# ES32F0xx register map
File version: 1.0
Registers are 32-bit, read-write, reset 0x0 unless marked. A register's access mark holds for its fields unless they carry their own. Offsets are from the block's base; [hi:lo] are bit positions; {n}, {i} and the like mark numbered series; 'fields as' and 'values as' point back to an identical list.

## USART0 — Universal Synchronous
Base 0x40005000
Same registers: USART1 0x40005400
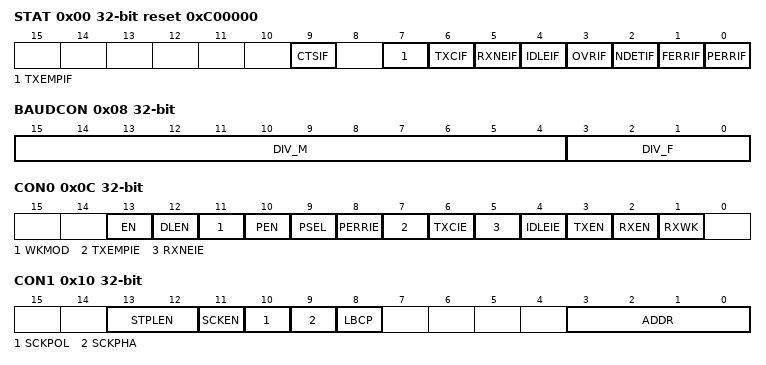
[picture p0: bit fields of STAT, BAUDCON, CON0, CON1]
0x00 STAT read reset 0xC00000
  [9] CTSIF, [7] TXEMPIF, [6] TXCIF, [5] RXNEIF, [4] IDLEIF, [3] OVRIF, [2] NDETIF, [1] FERRIF, [0] PERRIF
0x04 DATA
  [8:0] VAL
0x08 BAUDCON
  [15:4] DIV_M, [3:0] DIV_F
0x0C CON0
  [13] EN, [12] DLEN, [11] WKMOD, [10] PEN, [9] PSEL, [8] PERRIE, [7] TXEMPIE, [6] TXCIE, [5] RXNEIE, [4] IDLEIE, [3] TXEN, [2] RXEN, [1] RXWK
0x10 CON1
  [13:12] STPLEN, [11] SCKEN, [10] SCKPOL, [9] SCKPHA, [8] LBCP, [3:0] ADDR
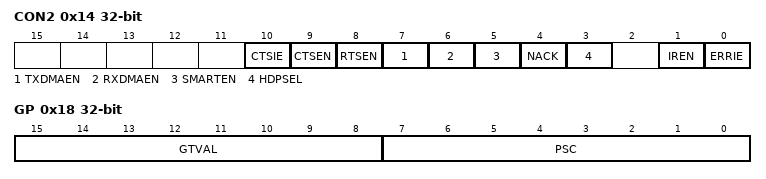
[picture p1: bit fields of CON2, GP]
0x14 CON2
  [10] CTSIE, [9] CTSEN, [8] RTSEN, [7] TXDMAEN, [6] RXDMAEN, [5] SMARTEN, [4] NACK, [3] HDPSEL, [1] IREN, [0] ERRIE
0x18 GP
  [15:8] GTVAL, [7:0] PSC

## UART0 — Universal Asynchronous
Base 0x40004000
Same registers: UART1 0x40004400, UART2 0x40004800, UART3 0x40004C00
0x00 RBR ro
  [8:0] RBR
0x04 TBR
  [8:0] TBR
0x08 BRR
  [15:0] BRR
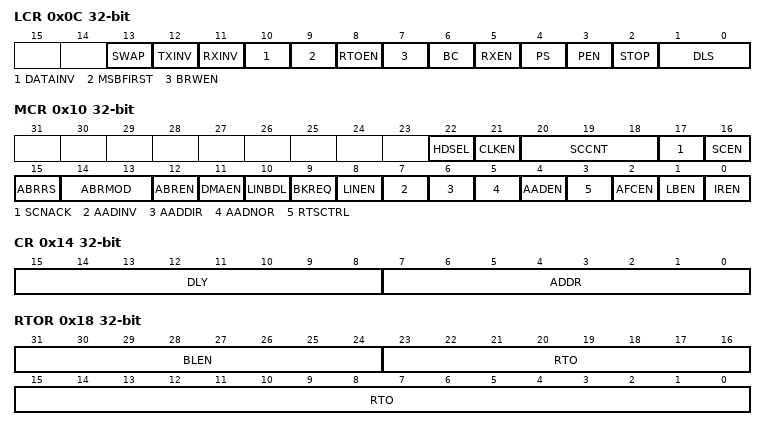
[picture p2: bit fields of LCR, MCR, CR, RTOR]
0x0C LCR
  [13] SWAP, [12] TXINV, [11] RXINV, [10] DATAINV, [9] MSBFIRST, [8] RTOEN, [7] BRWEN, [6] BC, [5] RXEN, [4] PS, [3] PEN, [2] STOP, [1:0] DLS
0x10 MCR
  [22] HDSEL, [21] CLKEN, [20:18] SCCNT, [17] SCNACK, [16] SCEN, [15] ABRRS, [14:13] ABRMOD, [12] ABREN, [11] DMAEN, [10] LINBDL, [9] BKREQ, [8] LINEN, [7] AADINV, [6] AADDIR, [5] AADNOR, [4] AADEN, [3] RTSCTRL, [2] AFCEN, [1] LBEN, [0] IREN
0x14 CR
  [15:8] DLY, [7:0] ADDR
0x18 RTOR
  [31:24] BLEN, [23:0] RTO
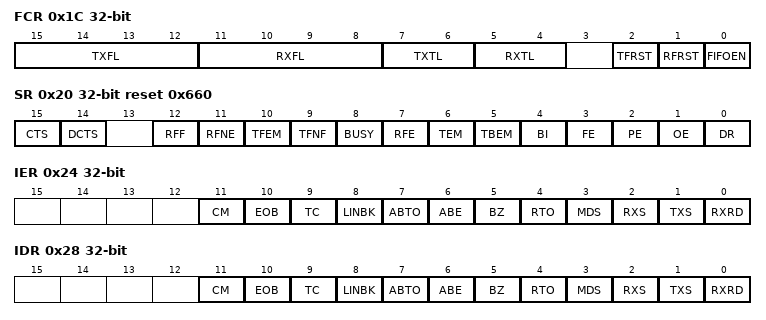
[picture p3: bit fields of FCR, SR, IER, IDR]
0x1C FCR
  [15:12] TXFL, [11:8] RXFL, [7:6] TXTL, [5:4] RXTL, [2] TFRST, [1] RFRST, [0] FIFOEN
0x20 SR ro reset 0x660
  [15] CTS, [14] DCTS, [12] RFF, [11] RFNE, [10] TFEM, [9] TFNF, [8] BUSY, [7] RFE, [6] TEM, [5] TBEM, [4] BI, [3] FE, [2] PE, [1] OE, [0] DR
0x24 IER
  [11] CM, [10] EOB, [9] TC, [8] LINBK, [7] ABTO, [6] ABE, [5] BZ, [4] RTO, [3] MDS, [2] RXS, [1] TXS, [0] RXRD
0x28 IDR
  fields as IER
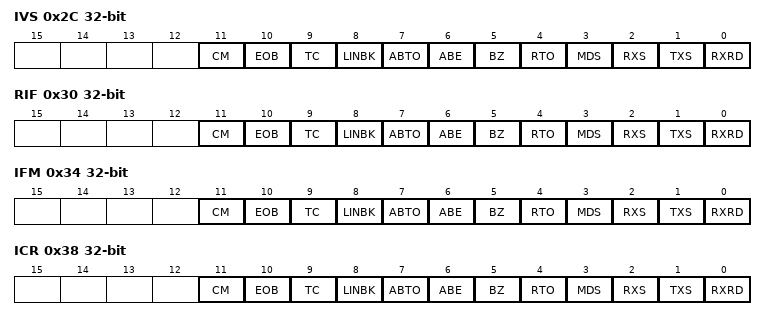
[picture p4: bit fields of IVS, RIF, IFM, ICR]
0x2C IVS ro
  fields as IER
0x30 RIF ro
  fields as IER
0x34 IFM ro
  fields as IER
0x38 ICR
  fields as IER

## ADC0 — Analog-to-digital converter
Base 0x40042000
Same registers: ADC1 0x40042400
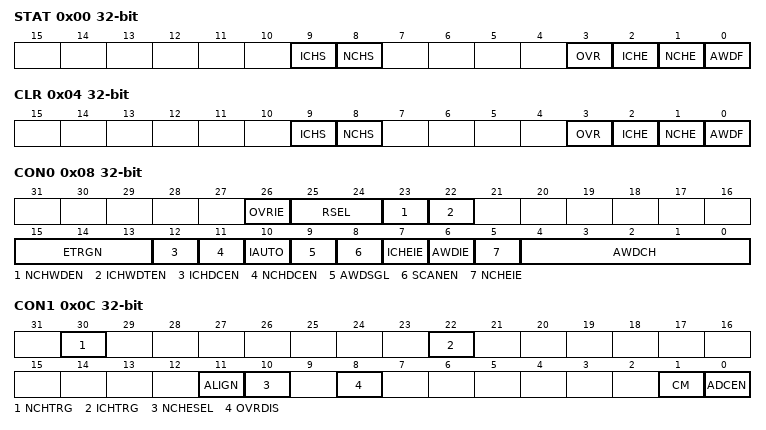
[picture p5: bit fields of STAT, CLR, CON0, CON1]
0x00 STAT read
  [9] ICHS, [8] NCHS, [3] OVR, [2] ICHE, [1] NCHE, [0] AWDF
0x04 CLR write
  [9] ICHS, [8] NCHS, [3] OVR, [2] ICHE, [1] NCHE, [0] AWDF
0x08 CON0
  [26] OVRIE, [25:24] RSEL, [23] NCHWDEN, [22] ICHWDTEN, [15:13] ETRGN, [12] ICHDCEN, [11] NCHDCEN, [10] IAUTO, [9] AWDSGL, [8] SCANEN, [7] ICHEIE, [6] AWDIE, [5] NCHEIE, [4:0] AWDCH
0x0C CON1
  [30] NCHTRG, [22] ICHTRG, [11] ALIGN, [10] NCHESEL, [8] OVRDIS, [1] CM, [0] ADCEN
0x10 SMPT1
  [31:0] CHT
0x14 SMPT2
  [7:0] CHT
{0x14+4i} ICHOFF{i} (i=1..4)
  [11:0] IOFF
0x28 WDTH reset 0xFFF
  [11:0] HT
0x2C WDTL
  [11:0] LT
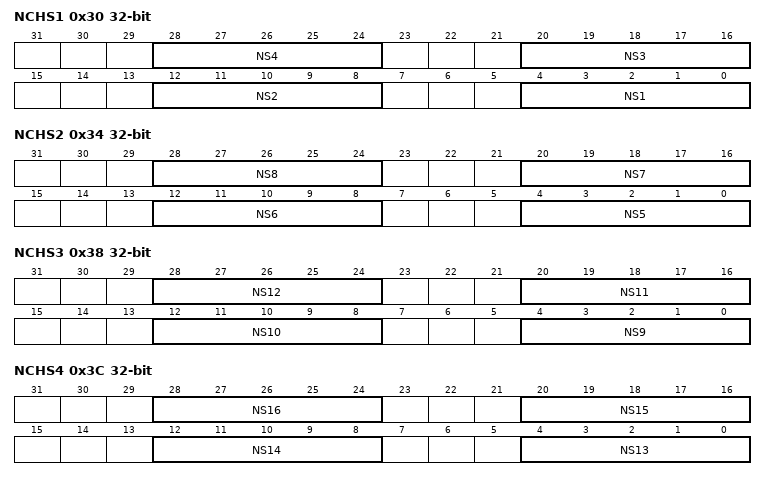
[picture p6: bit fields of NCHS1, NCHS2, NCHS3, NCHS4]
0x30 NCHS1
  [8n-4:8n-8] NS{n} (n=1..4)
0x34 NCHS2
  [8n-36:8n-40] NS{n} (n=5..8)
0x38 NCHS3
  [8n-68:8n-72] NS{n} (n=9..12)
0x3C NCHS4
  [8n-100:8n-104] NS{n} (n=13..16)
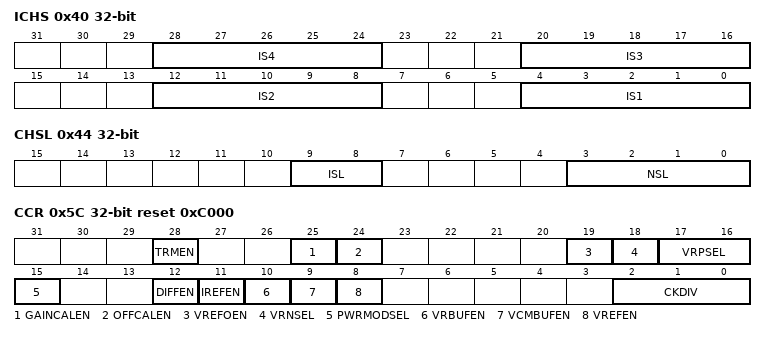
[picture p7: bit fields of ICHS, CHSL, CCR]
0x40 ICHS
  [8n-4:8n-8] IS{n} (n=1..4)
0x44 CHSL
  [9:8] ISL, [3:0] NSL
{0x44+4i} ICHDR{i} read (i=1..4)
  [15:0] VAL
0x58 NCHDR read
  [15:0] VAL
0x5C CCR reset 0xC000
  [28] TRMEN, [25] GAINCALEN, [24] OFFCALEN, [19] VREFOEN, [18] VRNSEL, [17:16] VRPSEL, [15] PWRMODSEL, [12] DIFFEN, [11] IREFEN, [10] VRBUFEN, [9] VCMBUFEN, [8] VREFEN, [2:0] CKDIV

## ACMP0
Base 0x40043000
Same registers: ACMP1 0x40043400
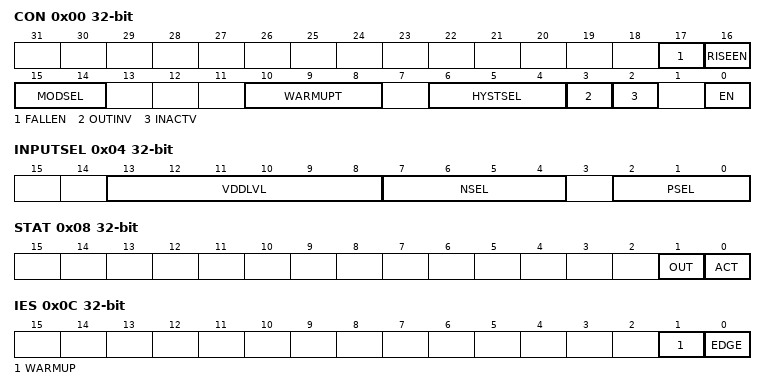
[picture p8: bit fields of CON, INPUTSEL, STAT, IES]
0x00 CON
  [17] FALLEN, [16] RISEEN, [15:14] MODSEL, [10:8] WARMUPT, [6:4] HYSTSEL, [3] OUTINV, [2] INACTV, [0] EN
0x04 INPUTSEL
  [13:8] VDDLVL, [7:4] NSEL, [2:0] PSEL
0x08 STAT read
  [1] OUT, [0] ACT
0x0C IES write
  [1] WARMUP, [0] EDGE
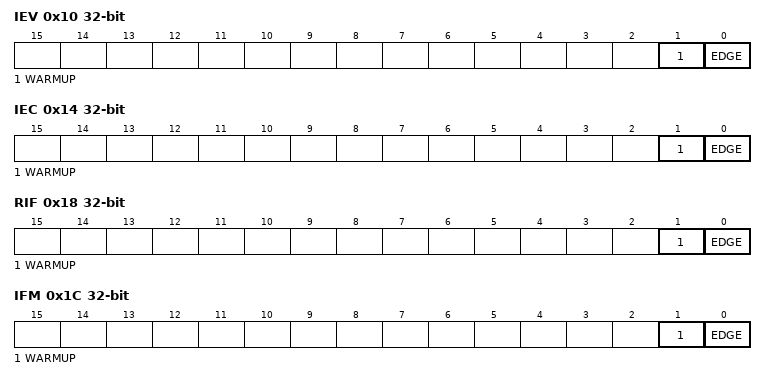
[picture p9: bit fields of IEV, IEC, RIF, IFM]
0x10 IEV read
  [1] WARMUP, [0] EDGE
0x14 IEC write
  [1] WARMUP, [0] EDGE
0x18 RIF read
  [1] WARMUP, [0] EDGE
0x1C IFM write
  [1] WARMUP, [0] EDGE
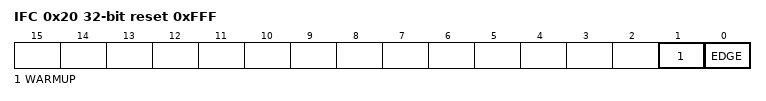
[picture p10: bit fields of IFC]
0x20 IFC write reset 0xFFF
  [1] WARMUP, [0] EDGE
0x24 PORT
  [0] PEN

## TSENSE — TSENSE Manage Uint
Base 0x40048800
0x00 WPR read reset 0x1
  [0] WP
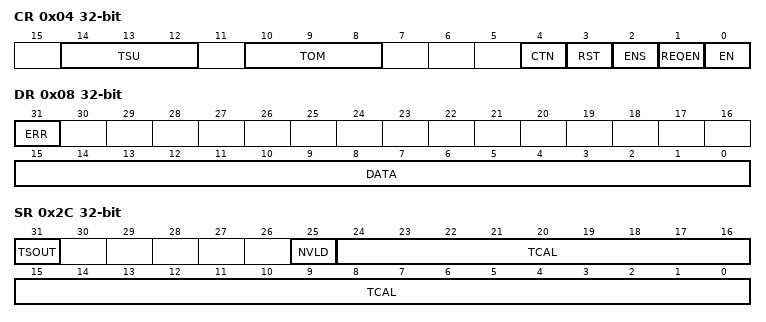
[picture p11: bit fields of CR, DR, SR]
0x04 CR
  [14:12] TSU, [10:8] TOM, [4] CTN, [3] RST, [2] ENS, [1] REQEN, [0] EN
0x08 DR read
  [31] ERR, [15:0] DATA
0x0C PSR
  [7:0] PRS
0x10 IE
  [0] TSENSE
0x14 IF read
  [0] TSENSE
0x18 IFCR
  [0] TSENSE
0x1C LTGR
  [20:0] LTG
0x20 HTGR
  [20:0] HTG
0x24 TBDR
  [15:0] TBD
0x28 TCALBDR
  [16:0] TCAL
0x2C SR read
  [31] TSOUT, [25] NVLD, [24:0] TCAL

## BKPC — Backup Manage Uint
Base 0x40048000
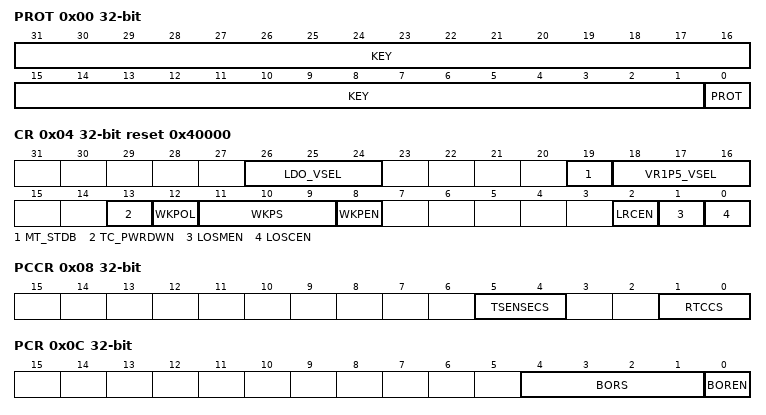
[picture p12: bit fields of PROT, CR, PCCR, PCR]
0x00 PROT
  [31:1] KEY, [0] PROT
0x04 CR reset 0x40000
  [26:24] LDO_VSEL, [19] MT_STDB, [18:16] VR1P5_VSEL, [13] TC_PWRDWN, [12] WKPOL, [11:9] WKPS, [8] WKPEN, [2] LRCEN, [1] LOSMEN, [0] LOSCEN
0x08 PCCR
  [5:4] TSENSECS, [1:0] RTCCS
0x0C PCR
  [4:1] BORS, [0] BOREN

## TRNG
Base 0x40085C00
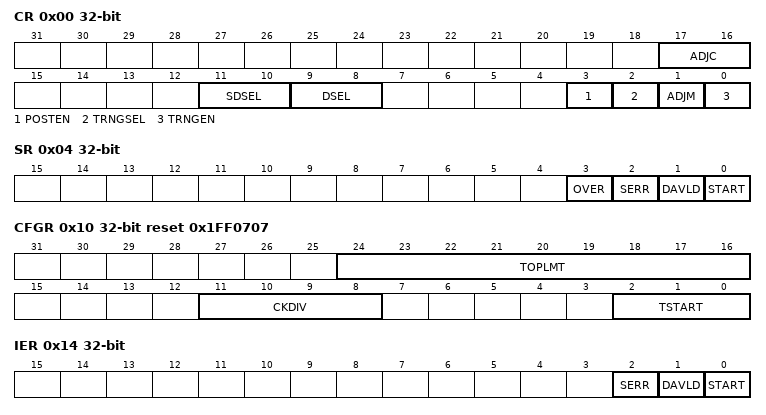
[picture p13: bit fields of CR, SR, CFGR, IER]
0x00 CR
  [17:16] ADJC, [11:10] SDSEL, [9:8] DSEL, [3] POSTEN, [2] TRNGSEL, [1] ADJM, [0] TRNGEN
0x04 SR read
  [3] OVER, [2] SERR, [1] DAVLD, [0] START
0x08 DR read
  [31:0] DATA
0x0C SEED
0x10 CFGR reset 0x1FF0707
  [24:16] TOPLMT, [11:8] CKDIV, [2:0] TSTART
0x14 IER
  [2] SERR, [1] DAVLD, [0] START
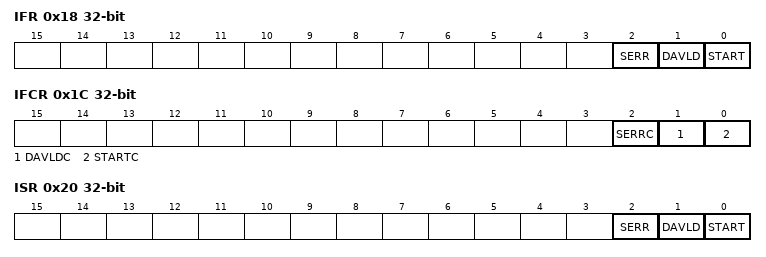
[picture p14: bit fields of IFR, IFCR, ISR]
0x18 IFR read
  [2] SERR, [1] DAVLD, [0] START
0x1C IFCR write
  [2] SERRC, [1] DAVLDC, [0] STARTC
0x20 ISR read
  [2] SERR, [1] DAVLD, [0] START

## WWDT — Watch Dog Timer
Base 0x40046000
0x00 LOAD
0x04 VALUE ro
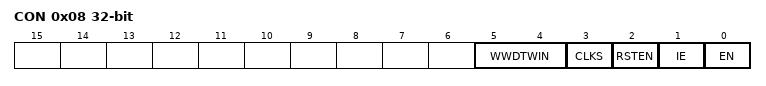
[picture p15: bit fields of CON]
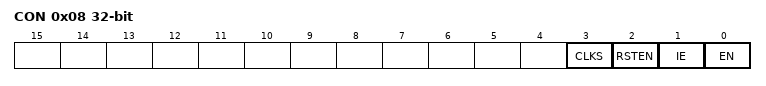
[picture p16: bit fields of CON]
0x08 CON
  [5:4] WWDTWIN, [3] CLKS, [2] RSTEN, [1] IE, [0] EN
0x0C INTCLR
0x10 RIS ro
  [0] WWDTIF
0x100 LOCK reset 0x1
  [0] LOCK

## IWDT — Watch Dog Timer
Base 0x40046400
0x00 LOAD write reset 0x80000
0x04 VALUE read reset 0xFFFFFFFF
0x08 CON
  [3] CLKS, [2] RSTEN, [1] IE, [0] EN
0x0C INTCLR write
0x10 RIS read
  [0] WDTIF
0x100 LOCK read reset 0x1
  [0] LOCK

## SYSCFG — System Configure
Base 0x40080000
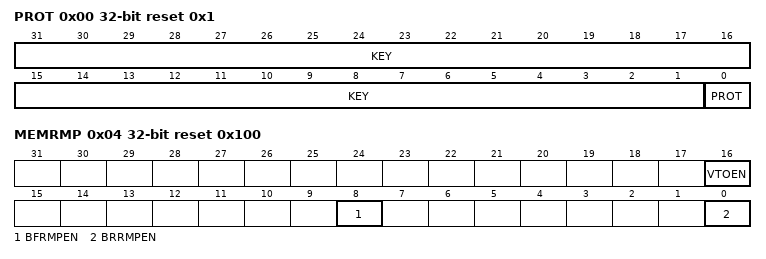
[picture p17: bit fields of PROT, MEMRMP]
0x00 PROT reset 0x1
  [31:1] KEY, [0] PROT
0x04 MEMRMP reset 0x100
  [16] VTOEN, [8] BFRMPEN, [0] BRRMPEN
0x08 VTOR
  [29:0] VTO

## DBGCON — Debug Control Uint
Base 0x4004A000
0x00 IDCODE read
  [31:16] REV_ID, [15:12] CORE_ID, [11:0] DEV_ID
0x04 CR
  [3] DBG_STANDBY, [2] DBG_STOP2, [1] DBG_STOP1, [0] DBG_SLEEP
0x08 APB1FZ
  [12] CAN_STOP, [9] I2C1_SMBUS_TO, [8] I2C0_SMBUS_TO, [n] TIM{n}_STOP (n=0..7)
0x0C APB2FZ
  [10] RTC_STOP, [9] WWDT_STOP, [8] IWDT_STOP, [0] LPTIM0_STOP
